# ECM3531 register map
Vendor: EtaCompute; Series: ECM35xx; File version: 1.0.0
CPU: CM3 r1p1, little endian, MPU, no FPU, 3 interrupt priority bits
Registers are 32-bit, read-write, reset 0x0 unless marked. A register's access mark holds for its fields unless they carry their own. Offsets are from the block's base; [hi:lo] are bit positions; {n}, {i} and the like mark numbered series.

## GPIO — The General Purpose I/O (GPIO) Device provides programmable access to the pins of the chip from within the M3 complex
Base 0x40010000
0x00 CSR — Control and Status Register for GPIO inside of M3 Complex
  [0] TICK2GPIOIN — Enable a few clock sources as inputs for GPIO[7:0] instead of the usual pad inputs This assumes these GPIOs are normally used as outputs to drive LEDs on a board This allow these bits to simultaneously serve as dedicated outputs and also as dedicated inputs
    1=ENABLE (Enable ticks to GPIO inputs); 0=DISABLE (Do not use the tick inputs)
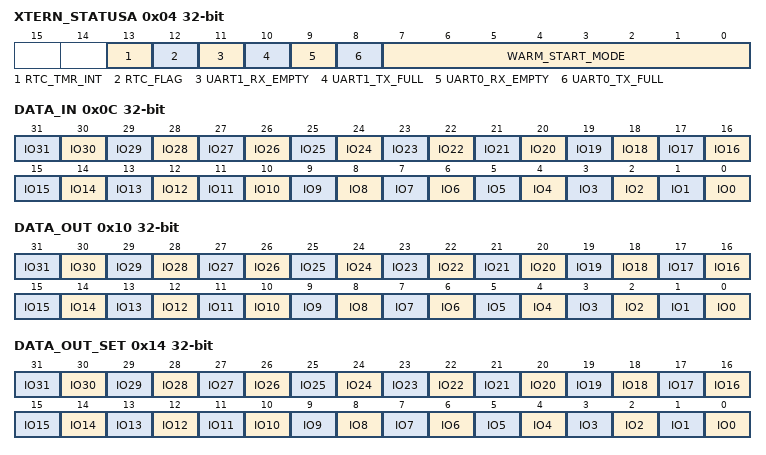
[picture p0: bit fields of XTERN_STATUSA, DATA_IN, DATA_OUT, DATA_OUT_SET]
0x04 XTERN_STATUSA — Quick read of various external status bits
  [13] RTC_TMR_INT ro — This read only bits provides access to the RTC TIMER interrupt status bit
  [12] RTC_FLAG ro — This read only bits toggles every time the RTC time of day counter increments (once per second) It is used to guarantee safe reads of the current time of day
  [11] UART1_RX_EMPTY ro — This read only bits tell driver level code when there is at least one byte to the UART1 receiver FIFO
  [10] UART1_TX_FULL ro — This read only bits tell driver level code when there is room to add at least one more byte to the UART1 transmitter FIFO
  [9] UART0_RX_EMPTY ro — This read only bits tell driver level code when there is at least one byte to the UART0 receiver FIFO
  [8] UART0_TX_FULL ro — This read only bits tell driver level code when there is room to add at least one more byte to the UART0 transmitter FIFO
  [7:0] WARM_START_MODE ro — These read only bits tell the BOOTROM how to warm start and if it should warm start Anything greater than 0x8 is a warm start
    0=NORMAL_COLD_START (Normal cold start in SRAM or flash); 1=FORCE_COLD_START_IN_FLASH (Force cold start in flash even if valid SRAM program present)
0x0C DATA_IN — Data INPUT for each PAD
  [n] IO{n} ro (n=0..31) — Input bits from each Pad/Pin
0x10 DATA_OUT — Data Output for each PAD
  [n] IO{n} wo (n=0..31) — Set or clear output bit
0x14 DATA_OUT_SET — Set 1 to set Data Output to one
  [n] IO{n} wo (n=0..31) — Set to 1 to set output bit
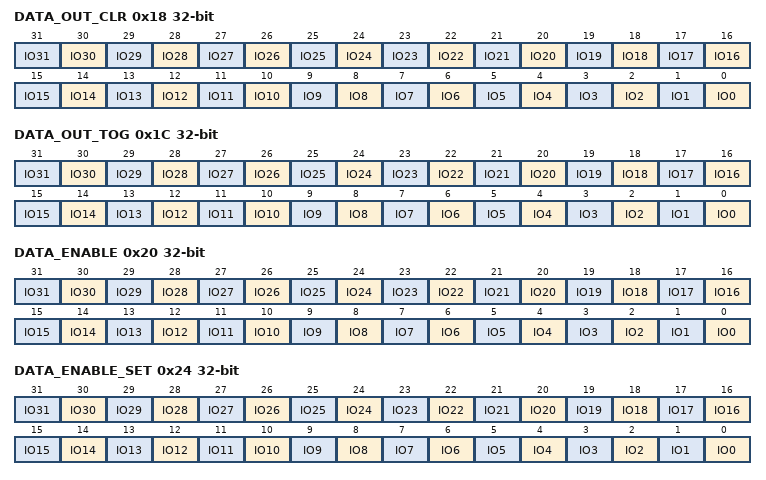
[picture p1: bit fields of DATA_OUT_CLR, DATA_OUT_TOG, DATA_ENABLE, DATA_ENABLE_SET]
0x18 DATA_OUT_CLR — Set 1 to set Data Output to zero
  [n] IO{n} wo (n=0..31) — Set to 1 to clear output bit
0x1C DATA_OUT_TOG — Set 1 to toggle Data Output to zero
  [n] IO{n} wo (n=0..31) — Set to 1 toggle output bit
0x20 DATA_ENABLE — Data Output Enable for each PAD
  [n] IO{n} wo (n=0..31) — Set to 1 to enable output bit
0x24 DATA_ENABLE_SET — Set Data Output Enable for each PAD
  [n] IO{n} wo (n=0..31) — Set to 1 to set enable output bit
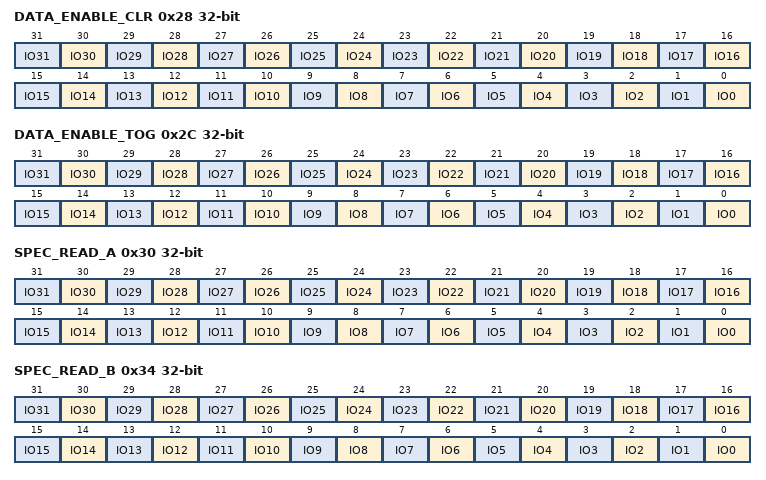
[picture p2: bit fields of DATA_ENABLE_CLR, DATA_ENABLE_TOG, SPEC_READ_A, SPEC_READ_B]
0x28 DATA_ENABLE_CLR — Clear Data Output Enable for each PAD
  [n] IO{n} wo (n=0..31) — Set to 1 to clr enable output bit
0x2C DATA_ENABLE_TOG — Toggle Data Output Enable for each PAD
  [n] IO{n} wo (n=0..31) — Set to 1 toggle enable output bit
0x30 SPEC_READ_A — Provide a read only value for speculative read support on the peripheral bus
  [n] IO{n} ro (n=0..31) — Input bits from each Pad/Pin
0x34 SPEC_READ_B — Provide a read only value for speculative read support on the peripheral bus
  [n] IO{n} ro (n=0..31) — Input bits from each Pad/Pin
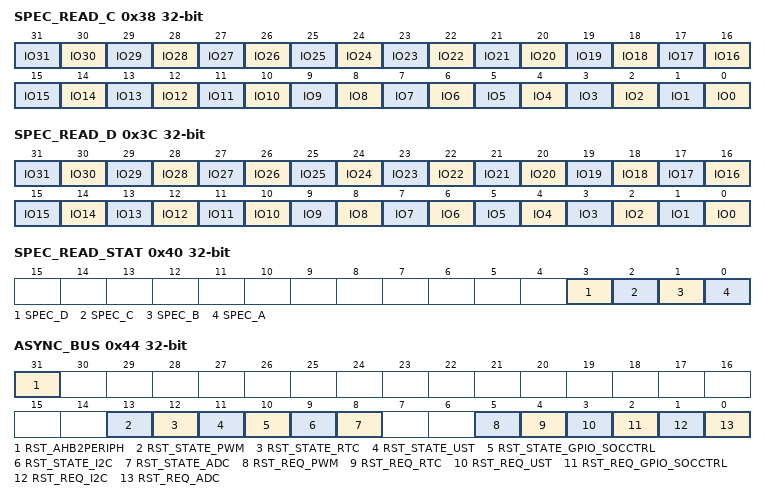
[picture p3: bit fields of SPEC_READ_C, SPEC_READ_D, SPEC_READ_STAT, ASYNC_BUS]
0x38 SPEC_READ_C — Provide a read only value for speculative read support on the peripheral bus
  [n] IO{n} ro (n=0..31) — Input bits from each Pad/Pin
0x3C SPEC_READ_D — Provide a read only value for speculative read support on the peripheral bus
  [n] IO{n} ro (n=0..31) — Input bits from each Pad/Pin
0x40 SPEC_READ_STAT — Provide a status bit for each of the four speculative read contexts
  [all] fields
    1=READY (Result is ready)
  [3] SPEC_D — Speculative read data available for read Write a one to this bit to clear it
  [2] SPEC_C — Speculative read data available for read Write a one to this bit to clear it
  [1] SPEC_B — Speculative read data available for read Write a one to this bit to clear it
  [0] SPEC_A — Speculative read data available for read Write a one to this bit to clear it
0x44 ASYNC_BUS — Control fields for the asynchronous buses
  [31] RST_AHB2PERIPH wo — Flush the buffer and reset the state of the AHB2PERIPH logic This will also issue a reset request on all async buses
    1=RESET (Assert the reset)
  [13] RST_STATE_PWM ro — Actual reset response from the slave
    0=RESET (Slave reset); 1=ACTIVE (Slave active)
  [12] RST_STATE_RTC ro — Actual reset response from the slave
    0=RESET (Slave reset); 1=ACTIVE (Slave active)
  [11] RST_STATE_UST ro — Actual reset response from the slave
    0=RESET (Slave reset); 1=ACTIVE (Slave active)
  [10] RST_STATE_GPIO_SOCCTRL ro — Actual reset response from the slave
    0=RESET (Slave reset); 1=ACTIVE (Slave active)
  [9] RST_STATE_I2C ro — Actual reset response from the slave
    0=RESET (Slave reset); 1=ACTIVE (Slave active)
  [8] RST_STATE_ADC ro — Actual reset response from the slave
    0=RESET (Slave reset); 1=ACTIVE (Slave active)
  [5] RST_REQ_PWM — Issue a reset request from the PWM async bus master Field will remain set until reset is complete
    1=RESET (Assert the reset request)
  [4] RST_REQ_RTC — Issue a reset request from the RTC async bus master Field will remain set until reset is complete
    1=RESET (Assert the reset request)
  [3] RST_REQ_UST — Issue a reset request from the UST async bus master Field will remain set until reset is complete
    1=RESET (Assert the reset request)
  [2] RST_REQ_GPIO_SOCCTRL — Issue a reset request from the GPIO/SOCCTRL async bus master Field will remain set until reset is complete
    1=RESET (Assert the reset request)
  [1] RST_REQ_I2C — Issue a reset request from the I2C async bus master Field will remain set until reset is complete
    1=RESET (Assert the reset request)
  [0] RST_REQ_ADC — Issue a reset request from the ADC async bus master Field will remain set until reset is complete
    1=RESET (Assert the reset request)
0x48 DEBUG0_READ_ONLY — Provide a read only value for diagnostics
  [31:0] VALUE ro — Debug Read Only Value for Diagnostics
0x4C DEBUG1_READ_ONLY — Provide a read only value for diagnostics
  [31:0] VALUE ro — Debug Read Only Value for Diagnostics

## Notices in the file
Copyright (C) 2018 Eta Compute, Inc. All rights reserved.
Licensed under the Apache License, Version 2.0 (the "License");
you may not use this file except in compliance with the License.
You may obtain a copy of the License at
http://www.apache.org/licenses/LICENSE-2.0
Unless required by applicable law or agreed to in writing, software
distributed under the License is distributed on an "AS IS" BASIS,
WITHOUT WARRANTIES OR CONDITIONS OF ANY KIND, either express or implied.
See the License for the specific language governing permissions and
limitations under the License.
